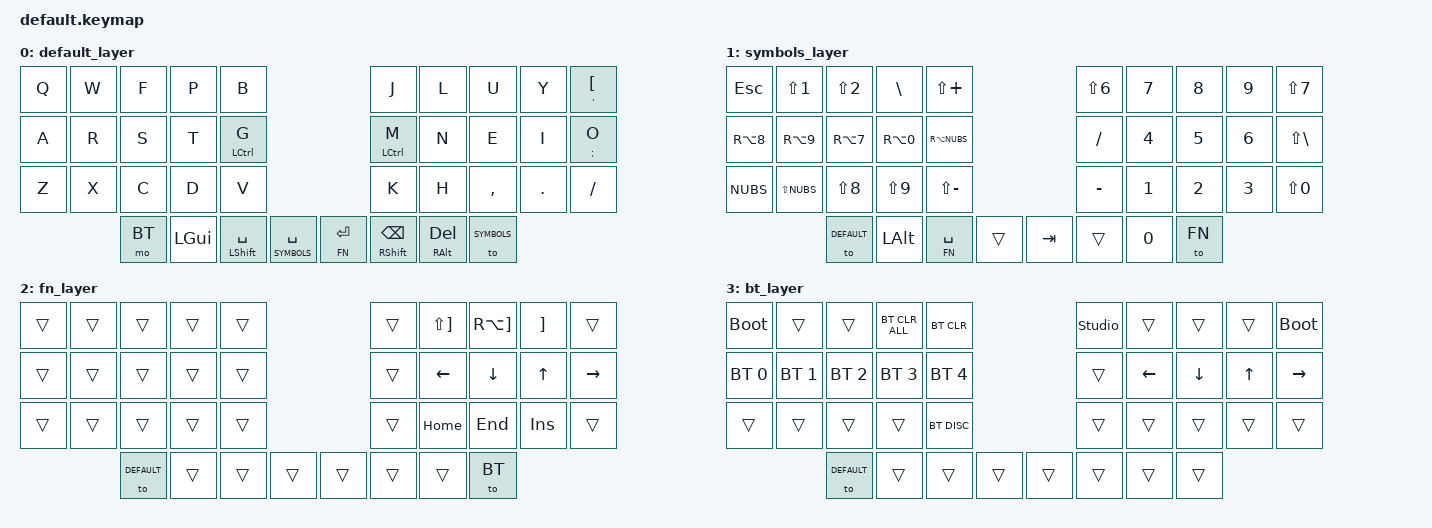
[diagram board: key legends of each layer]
#include <behaviors.dtsi>
#include <dt-bindings/zmk/keys.h>
#include <dt-bindings/zmk/bt.h>

#define DEFAULT     0
#define SYMBOLS     1
#define FN          2
#define BT          3


/ {
        behaviors {
            tt: this_or_that {
                compatible = "zmk,behavior-hold-tap";
                #binding-cells = <2>;
                tapping-term-ms = <200>;
                quick-tap-ms = <0>;
                flavor = "tap-preferred";
                bindings = <&kp>, <&kp>;
            };
        };

        keymap {
        compatible = "zmk,keymap";

        default_layer {
            bindings = <
                &kp Q       &kp W       &kp F       &kp P           &kp B                                               &kp J           &kp L       &kp U           &kp Y       &tt SQT LBKT
                &kp A       &kp R       &kp S       &kp T           &tt LCTRL G                                         &tt LCTRL M     &kp N       &kp E           &kp I       &tt SEMI O
                &kp Z       &kp X       &kp C       &kp D           &kp V                                               &kp K           &kp H       &kp COMMA       &kp DOT     &kp FSLH
                                        &mo BT      &kp LGUI        &mt LSHFT SPACE &lt SYMBOLS SPACE       &lt FN RETURN &mt RSHIFT BSPC &mt RALT DEL&to SYMBOLS
            >;
        };

        symbols_layer {
            bindings = <
                &kp ESC     &kp LS(N1)  &kp LS(N2)  &kp BACKSLASH   &kp LS(PLUS)                                        &kp LS(N6)      &kp N7       &kp N8         &kp N9      &kp LS(N7)
                &kp RA(N8)  &kp RA(N9)  &kp RA(N7)  &kp RA(N0)      &kp RA(NUBS)                                        &kp FSLH        &kp N4       &kp N5         &kp N6      &kp LS(BACKSLASH)
                &kp NUBS    &kp LS(NUBS)&kp LS(N8)  &kp LS(N9)      &kp LS(MINUS)                                       &kp MINUS       &kp N1       &kp N2         &kp N3      &kp LS(N0)
                                        &to DEFAULT &kp LALT        &lt FN SPACE     &trans                &kp TAB      &trans          &kp N0       &to FN
            >;
        };
        
        fn_layer {
            bindings = <
                &trans      &trans      &trans      &trans          &trans                                              &trans          &kp LS(RBKT) &kp RA(RBKT)   &kp RBKT    &trans
                &trans      &trans      &trans      &trans          &trans                                              &trans          &kp LEFT     &kp DOWN       &kp UP      &kp RIGHT
                &trans      &trans      &trans      &trans          &trans                                              &trans          &kp HOME     &kp END        &kp INS     &trans
                                        &to DEFAULT &trans          &trans          &trans                  &trans      &trans          &trans       &to BT
            >;
        };

        bt_layer {
            bindings = <
                &bootloader &trans      &trans      &bt BT_CLR_ALL  &bt BT_CLR                                          &studio_unlock  &trans       &trans         &trans      &bootloader
                &bt BT_SEL 0&bt BT_SEL 1&bt BT_SEL 2&bt BT_SEL 3    &bt BT_SEL 4                                        &trans          &kp LEFT     &kp DOWN       &kp UP      &kp RIGHT 
                &trans      &trans      &trans      &trans          &bt BT_DISC                                         &trans          &trans       &trans         &trans      &trans
                                        &to DEFAULT &trans          &trans          &trans                   &trans     &trans          &trans       &trans
            >;
        };
    };
};
